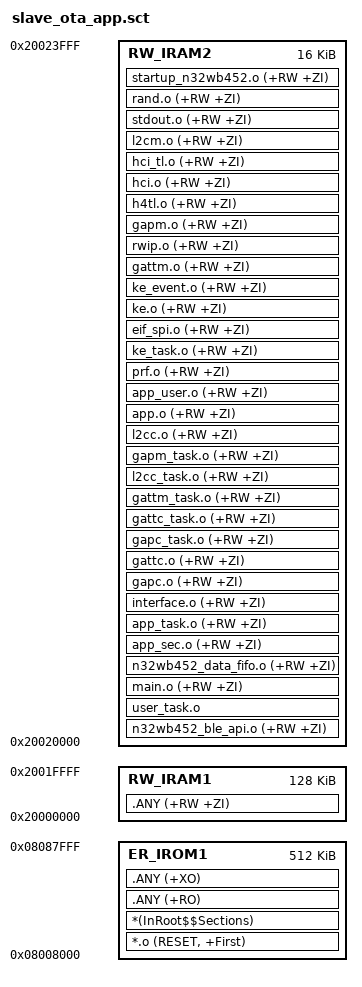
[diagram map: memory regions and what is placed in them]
; *************************************************************
; *** Scatter-Loading Description File generated by uVision ***
; *************************************************************

LR_IROM1 0x08008000 0x00080000  {    ; load region size_region
  ER_IROM1 0x08008000 0x00080000  {  ; load address = execution address
   *.o (RESET, +First)
   *(InRoot$$Sections)
   .ANY (+RO)
   .ANY (+XO)
  }
  
  RW_IRAM2 0x20020000 0x00004000  {; powerdown variables
   n32wb452_ble_api.o (+RW +ZI)
   user_task.o ;(+RW +ZI)
   main.o (+RW +ZI)
   n32wb452_data_fifo.o (+RW +ZI)
   app_sec.o (+RW +ZI)
   app_task.o (+RW +ZI)
   interface.o (+RW +ZI)
   gapc.o (+RW +ZI)
   gattc.o (+RW +ZI)
   gapc_task.o (+RW +ZI)
   gattc_task.o (+RW +ZI)
   gattm_task.o (+RW +ZI)
   l2cc_task.o (+RW +ZI)
   gapm_task.o (+RW +ZI)
   l2cc.o (+RW +ZI)
   app.o (+RW +ZI)
   app_user.o (+RW +ZI)
   prf.o (+RW +ZI)
   ke_task.o (+RW +ZI)
   eif_spi.o (+RW +ZI)
   ke.o (+RW +ZI)
   ke_event.o (+RW +ZI)
   gattm.o (+RW +ZI)
   rwip.o (+RW +ZI)
   gapm.o (+RW +ZI)
   h4tl.o (+RW +ZI)
   hci.o (+RW +ZI)
   hci_tl.o (+RW +ZI)
   l2cm.o (+RW +ZI)
   stdout.o (+RW +ZI)
   rand.o (+RW +ZI)
   startup_n32wb452.o (+RW +ZI)
  }

  RW_IRAM1 0x20000000 0x00020000  {  ; RW data
   .ANY (+RW +ZI)
  }
}

